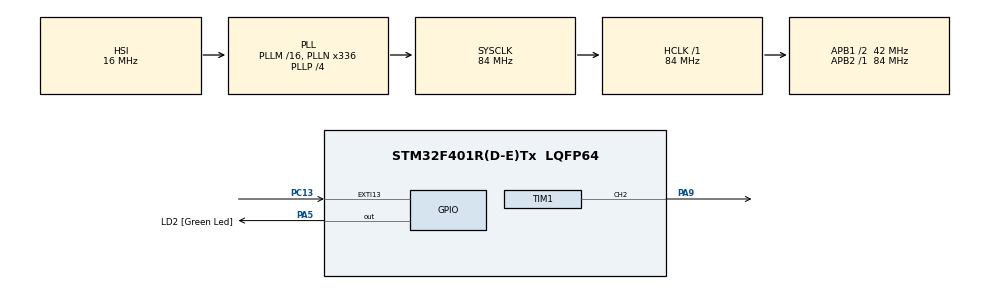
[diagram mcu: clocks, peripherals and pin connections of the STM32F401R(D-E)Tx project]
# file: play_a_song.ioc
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Mcu.Family=STM32F4
Mcu.Name=STM32F401R(D-E)Tx
Mcu.Package=LQFP64
NVIC.EXTI15_10_IRQn=true\:5\:0\:true\:false\:true\:true\:true
NVIC.PriorityGroup=NVIC_PRIORITYGROUP_4
NVIC.TIM1_BRK_TIM9_IRQn=true\:0\:0\:false\:false\:true\:true\:true
NVIC.TIM1_CC_IRQn=true\:0\:0\:false\:false\:true\:true\:true
NVIC.TIM1_TRG_COM_TIM11_IRQn=true\:0\:0\:false\:false\:true\:true\:true
NVIC.TIM1_UP_TIM10_IRQn=true\:0\:0\:false\:false\:true\:true\:true
NVIC.TIM2_IRQn=true\:0\:0\:false\:false\:true\:true\:true
PA13.GPIO_Label=TMS
PA13.Mode=Serial_Wire
PA13.Signal=SYS_JTMS-SWDIO
PA14.GPIO_Label=TCK
PA14.Mode=Serial_Wire
PA14.Signal=SYS_JTCK-SWCLK
PA5.GPIO_Label=LD2 [Green Led]
PA5.GPIO_Mode=GPIO_MODE_OUTPUT_PP
PA5.GPIO_PuPd=GPIO_NOPULL
PA5.GPIO_Speed=GPIO_SPEED_FREQ_LOW
PA5.Signal=GPIO_Output
PA9.Signal=S_TIM1_CH2
PB3.GPIO_Label=SWO
PB3.Signal=SYS_JTDO-SWO
PC13-ANTI_TAMP.Signal=GPXTI13
ProjectManager.HeapSize=0x200
ProjectManager.StackSize=0x400
ProjectManager.TargetToolchain=MDK-ARM V5
RCC.48MHZClocksFreq_Value=48000000
RCC.AHBFreq_Value=84000000
RCC.APB1CLKDivider=RCC_HCLK_DIV2
RCC.APB1Freq_Value=42000000
RCC.APB1TimFreq_Value=84000000
RCC.APB2Freq_Value=84000000
RCC.APB2TimFreq_Value=84000000
RCC.CortexFreq_Value=84000000
RCC.HCLKFreq_Value=84000000
RCC.HSE_VALUE=8000000
RCC.HSI_VALUE=16000000
RCC.LSE_VALUE=32768
RCC.PLLN=336
RCC.PLLP=RCC_PLLP_DIV4
RCC.PLLQ=7
RCC.SYSCLKFreq_VALUE=84000000
RCC.SYSCLKSource=RCC_SYSCLKSOURCE_PLLCLK
RCC.VCOOutputFreq_Value=336000000
SH.S_TIM1_CH2.0=TIM1_CH2,PWM Generation2 CH2
TIM1.Channel-PWM\ Generation2\ CH2=TIM_CHANNEL_2
TIM1.OCFastMode_PWM-PWM\ Generation2\ CH2=TIM_OCFAST_DISABLE
TIM1.Period=480-1
TIM1.Prescaler=84-1
TIM1.Pulse-PWM\ Generation2\ CH2=240-1
TIM2.Period=42-1
TIM2.Prescaler=2000-1
TIM2.TIM_MasterOutputTrigger=TIM_TRGO_OC1REF
TIM2.TIM_MasterSlaveMode=TIM_MASTERSLAVEMODE_DISABLE
VP_TIM1_VS_ClockSourceINT.Mode=Internal
VP_TIM2_VS_ClockSourceINT.Mode=Internal
board=NUCLEO-F401RE

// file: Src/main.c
/* USER CODE BEGIN Header */
/**
  ******************************************************************************
  * @file           : main.c
  * @brief          : Main program body
  ******************************************************************************
  * @attention
  *
  * <h2><center>&copy; Copyright (c) 2019 STMicroelectronics.
  * All rights reserved.</center></h2>
  *
  * This software component is licensed by ST under BSD 3-Clause license,
  * the "License"; You may not use this file except in compliance with the
  * License. You may obtain a copy of the License at:
  *                        opensource.org/licenses/BSD-3-Clause
  *
  ******************************************************************************
  */
/* USER CODE END Header */

#include "main.h"

/* USER CODE BEGIN PD */
#define MIN 60		// how many seconds in a minute
#define MS 1000		// milliseconds
#define BPM 35		// beats-per-minute

// Period of each note in ms
#define NOTE_B0    32396
#define NOTE_C1    30578
#define NOTE_CS1   28862
#define NOTE_D1    27242
#define NOTE_DS1   25713
#define NOTE_E1    24270
#define NOTE_F1    22908
#define NOTE_FS1   21622
#define NOTE_G1    20408
#define NOTE_GS1   19263
#define NOTE_A1    18182
#define NOTE_AS1   17161
#define NOTE_B1    16198
#define NOTE_C2    15289
#define NOTE_CS2   14431
#define NOTE_D2    13621
#define NOTE_DS2   12856
#define NOTE_E2    12135
#define NOTE_F2    11454
#define NOTE_FS2   10811
#define NOTE_G2    10204
#define NOTE_GS2    9631
#define NOTE_A2     9091
#define NOTE_AS2    8581
#define NOTE_B2     8099
#define NOTE_C3     7645
#define NOTE_CS3    7215
#define NOTE_D3     6810
#define NOTE_DS3    6428
#define NOTE_E3     6067
#define NOTE_F3     5727
#define NOTE_FS3    5405
#define NOTE_G3     5102
#define NOTE_GS3    4816
#define NOTE_A3     4545
#define NOTE_AS3    4290
#define NOTE_B3     4050
#define NOTE_C4     3822
#define NOTE_CS4    3608
#define NOTE_D4     3405
#define NOTE_DS4    3214
#define NOTE_E4     3034
#define NOTE_F4     2863
#define NOTE_FS4    2703
#define NOTE_G4     2551
#define NOTE_GS4    2408
#define NOTE_A4     2273
#define NOTE_AS4    2145
#define NOTE_B4     2025
#define NOTE_C5     1911
#define NOTE_CS5    1804
#define NOTE_D5     1703
#define NOTE_DS5    1607
#define NOTE_E5     1517
#define NOTE_F5     1432
#define NOTE_FS5    1351
#define NOTE_G5     1276
#define NOTE_GS5    1204
#define NOTE_A5     1136
#define NOTE_AS5    1073
#define NOTE_B5     1012
#define NOTE_C6      956
#define NOTE_CS6     902
#define NOTE_D6      851
#define NOTE_DS6     804
#define NOTE_E6      758
#define NOTE_F6      716
#define NOTE_FS6     676
#define NOTE_G6      638
#define NOTE_GS6     602
#define NOTE_A6      568
#define NOTE_AS6     536
#define NOTE_B6      506
#define NOTE_C7      478
#define NOTE_CS7     451
#define NOTE_D7      426
#define NOTE_DS7     402
#define NOTE_E7      379
#define NOTE_F7      358
#define NOTE_FS7     338
#define NOTE_G7      319
#define NOTE_GS7     301
#define NOTE_A7      284
#define NOTE_AS7     268
#define NOTE_B7      253
#define NOTE_C8      239
/* USER CODE END PD */

TIM_HandleTypeDef htim1;
TIM_HandleTypeDef htim2;

/* USER CODE BEGIN PV */
int notes[] = {
	NOTE_E7, NOTE_E7, 0, NOTE_E7,
  0, NOTE_C7, NOTE_E7, 0,
  NOTE_G7, 0, 0,  0,
  NOTE_G6, 0, 0, 0,

	NOTE_C7, 0, 0, NOTE_G6,
  0, 0, NOTE_E6, 0,
  0, NOTE_A6, 0, NOTE_B6,
  0, NOTE_AS6, NOTE_A6, 0,

  NOTE_G6, NOTE_E7, NOTE_G7,
  NOTE_A7, 0, NOTE_F7, NOTE_G7,
  0, NOTE_E7, 0, NOTE_C7,
  NOTE_D7, NOTE_B6, 0, 0,

  NOTE_C7, 0, 0, NOTE_G6,
  0, 0, NOTE_E6, 0,
  0, NOTE_A6, 0, NOTE_B6,
  0, NOTE_AS6, NOTE_A6, 0,

  NOTE_G6, NOTE_E7, NOTE_G7,
  NOTE_A7, 0, NOTE_F7, NOTE_G7,
  0, NOTE_E7, 0, NOTE_C7,
  NOTE_D7, NOTE_B6, 0, 0

};
int duration[] = {
	12, 12, 12, 12,
  12, 12, 12, 12,
  12, 12, 12, 12,
  12, 12, 12, 12,

	12, 12, 12, 12,
  12, 12, 12, 12,
  12, 12, 12, 12,
  12, 12, 12, 12,

  9, 9, 9,
  12, 12, 12, 12,
  12, 12, 12, 12,
  12, 12, 12, 12,

  12, 12, 12, 12,
  12, 12, 12, 12,
  12, 12, 12, 12,
  12, 12, 12, 12,

  9, 9, 9,
  12, 12, 12, 12,
  12, 12, 12, 12,
  12, 12, 12, 12

};	// beat
unsigned int counter = 0;
unsigned int i;
unsigned int note_duration, beat;
unsigned int flag = 0;
/* USER CODE END PV */

void SystemClock_Config(void);
static void MX_GPIO_Init(void);
static void MX_TIM1_Init(void);
static void MX_TIM2_Init(void);
/* USER CODE BEGIN PFP */
void play_song(void);
/* USER CODE END PFP */

int main(void)
{

  /* MCU Configuration--------------------------------------------------------*/

  /* Reset of all peripherals, Initializes the Flash interface and the Systick. */
  HAL_Init();

  /* Configure the system clock */
  SystemClock_Config();

  /* Initialize all configured peripherals */
  MX_GPIO_Init();
  MX_TIM1_Init();
  MX_TIM2_Init();
  /* USER CODE BEGIN 2 */
	beat = MIN*MS/BPM;
  /* USER CODE END 2 */

  /* Infinite loop */
  while (1)
  {

  }
}

void SystemClock_Config(void)
{
  RCC_OscInitTypeDef RCC_OscInitStruct = {0};
  RCC_ClkInitTypeDef RCC_ClkInitStruct = {0};

  /** Configure the main internal regulator output voltage
  */
  __HAL_RCC_PWR_CLK_ENABLE();
  __HAL_PWR_VOLTAGESCALING_CONFIG(PWR_REGULATOR_VOLTAGE_SCALE2);
  /** Initializes the CPU, AHB and APB busses clocks
  */
  RCC_OscInitStruct.OscillatorType = RCC_OSCILLATORTYPE_HSI;
  RCC_OscInitStruct.HSIState = RCC_HSI_ON;
  RCC_OscInitStruct.HSICalibrationValue = RCC_HSICALIBRATION_DEFAULT;
  RCC_OscInitStruct.PLL.PLLState = RCC_PLL_ON;
  RCC_OscInitStruct.PLL.PLLSource = RCC_PLLSOURCE_HSI;
  RCC_OscInitStruct.PLL.PLLM = 16;
  RCC_OscInitStruct.PLL.PLLN = 336;
  RCC_OscInitStruct.PLL.PLLP = RCC_PLLP_DIV4;
  RCC_OscInitStruct.PLL.PLLQ = 7;
  if (HAL_RCC_OscConfig(&RCC_OscInitStruct) != HAL_OK)
  {
    Error_Handler();
  }
  /** Initializes the CPU, AHB and APB busses clocks
  */
  RCC_ClkInitStruct.ClockType = RCC_CLOCKTYPE_HCLK|RCC_CLOCKTYPE_SYSCLK
                              |RCC_CLOCKTYPE_PCLK1|RCC_CLOCKTYPE_PCLK2;
  RCC_ClkInitStruct.SYSCLKSource = RCC_SYSCLKSOURCE_PLLCLK;
  RCC_ClkInitStruct.AHBCLKDivider = RCC_SYSCLK_DIV1;
  RCC_ClkInitStruct.APB1CLKDivider = RCC_HCLK_DIV2;
  RCC_ClkInitStruct.APB2CLKDivider = RCC_HCLK_DIV1;

  if (HAL_RCC_ClockConfig(&RCC_ClkInitStruct, FLASH_LATENCY_2) != HAL_OK)
  {
    Error_Handler();
  }
}

static void MX_TIM1_Init(void)
{

  TIM_ClockConfigTypeDef sClockSourceConfig = {0};
  TIM_MasterConfigTypeDef sMasterConfig = {0};
  TIM_OC_InitTypeDef sConfigOC = {0};
  TIM_BreakDeadTimeConfigTypeDef sBreakDeadTimeConfig = {0};

  htim1.Instance = TIM1;
  htim1.Init.Prescaler = 84-1;
  htim1.Init.CounterMode = TIM_COUNTERMODE_UP;
  htim1.Init.Period = 480-1;
  htim1.Init.ClockDivision = TIM_CLOCKDIVISION_DIV1;
  htim1.Init.RepetitionCounter = 0;
  htim1.Init.AutoReloadPreload = TIM_AUTORELOAD_PRELOAD_DISABLE;
  if (HAL_TIM_Base_Init(&htim1) != HAL_OK)
  {
    Error_Handler();
  }
  sClockSourceConfig.ClockSource = TIM_CLOCKSOURCE_INTERNAL;
  if (HAL_TIM_ConfigClockSource(&htim1, &sClockSourceConfig) != HAL_OK)
  {
    Error_Handler();
  }
  if (HAL_TIM_PWM_Init(&htim1) != HAL_OK)
  {
    Error_Handler();
  }
  sMasterConfig.MasterOutputTrigger = TIM_TRGO_RESET;
  sMasterConfig.MasterSlaveMode = TIM_MASTERSLAVEMODE_DISABLE;
  if (HAL_TIMEx_MasterConfigSynchronization(&htim1, &sMasterConfig) != HAL_OK)
  {
    Error_Handler();
  }
  sConfigOC.OCMode = TIM_OCMODE_PWM1;
  sConfigOC.Pulse = 240-1;
  sConfigOC.OCPolarity = TIM_OCPOLARITY_HIGH;
  sConfigOC.OCNPolarity = TIM_OCNPOLARITY_HIGH;
  sConfigOC.OCFastMode = TIM_OCFAST_DISABLE;
  sConfigOC.OCIdleState = TIM_OCIDLESTATE_RESET;
  sConfigOC.OCNIdleState = TIM_OCNIDLESTATE_RESET;
  if (HAL_TIM_PWM_ConfigChannel(&htim1, &sConfigOC, TIM_CHANNEL_2) != HAL_OK)
  {
    Error_Handler();
  }
  sBreakDeadTimeConfig.OffStateRunMode = TIM_OSSR_DISABLE;
  sBreakDeadTimeConfig.OffStateIDLEMode = TIM_OSSI_DISABLE;
  sBreakDeadTimeConfig.LockLevel = TIM_LOCKLEVEL_OFF;
  sBreakDeadTimeConfig.DeadTime = 0;
  sBreakDeadTimeConfig.BreakState = TIM_BREAK_DISABLE;
  sBreakDeadTimeConfig.BreakPolarity = TIM_BREAKPOLARITY_HIGH;
  sBreakDeadTimeConfig.AutomaticOutput = TIM_AUTOMATICOUTPUT_DISABLE;
  if (HAL_TIMEx_ConfigBreakDeadTime(&htim1, &sBreakDeadTimeConfig) != HAL_OK)
  {
    Error_Handler();
  }
  HAL_TIM_MspPostInit(&htim1);

}

static void MX_TIM2_Init(void)
{

  TIM_ClockConfigTypeDef sClockSourceConfig = {0};
  TIM_MasterConfigTypeDef sMasterConfig = {0};

  htim2.Instance = TIM2;
  htim2.Init.Prescaler = 2000-1;
  htim2.Init.CounterMode = TIM_COUNTERMODE_UP;
  htim2.Init.Period = 42-1;
  htim2.Init.ClockDivision = TIM_CLOCKDIVISION_DIV1;
  htim2.Init.AutoReloadPreload = TIM_AUTORELOAD_PRELOAD_DISABLE;
  if (HAL_TIM_Base_Init(&htim2) != HAL_OK)
  {
    Error_Handler();
  }
  sClockSourceConfig.ClockSource = TIM_CLOCKSOURCE_INTERNAL;
  if (HAL_TIM_ConfigClockSource(&htim2, &sClockSourceConfig) != HAL_OK)
  {
    Error_Handler();
  }
  sMasterConfig.MasterOutputTrigger = TIM_TRGO_OC1REF;
  sMasterConfig.MasterSlaveMode = TIM_MASTERSLAVEMODE_DISABLE;
  if (HAL_TIMEx_MasterConfigSynchronization(&htim2, &sMasterConfig) != HAL_OK)
  {
    Error_Handler();
  }

}

static void MX_GPIO_Init(void)
{
  GPIO_InitTypeDef GPIO_InitStruct = {0};

  /* GPIO Ports Clock Enable */
  __HAL_RCC_GPIOC_CLK_ENABLE();
  __HAL_RCC_GPIOA_CLK_ENABLE();
  __HAL_RCC_GPIOB_CLK_ENABLE();

  /*Configure GPIO pin Output Level */
  HAL_GPIO_WritePin(LD2_GPIO_Port, LD2_Pin, GPIO_PIN_RESET);

  /*Configure GPIO pin : PC13 */
  GPIO_InitStruct.Pin = GPIO_PIN_13;
  GPIO_InitStruct.Mode = GPIO_MODE_IT_RISING;
  GPIO_InitStruct.Pull = GPIO_NOPULL;
  HAL_GPIO_Init(GPIOC, &GPIO_InitStruct);

  /*Configure GPIO pin : LD2_Pin */
  GPIO_InitStruct.Pin = LD2_Pin;
  GPIO_InitStruct.Mode = GPIO_MODE_OUTPUT_PP;
  GPIO_InitStruct.Pull = GPIO_NOPULL;
  GPIO_InitStruct.Speed = GPIO_SPEED_FREQ_LOW;
  HAL_GPIO_Init(LD2_GPIO_Port, &GPIO_InitStruct);

  /* EXTI interrupt init*/
  HAL_NVIC_SetPriority(EXTI15_10_IRQn, 5, 0);
  HAL_NVIC_EnableIRQ(EXTI15_10_IRQn);

}

/* USER CODE BEGIN 4 */
void HAL_GPIO_EXTI_Callback(uint16_t GPIO_Pin)
{
	switch(GPIO_Pin)
	{
		case GPIO_PIN_13:
			flag = 1;
			i = 0;
			HAL_TIM_Base_Start_IT(&htim1); // prepare timer 1 to gen PWM
			__HAL_GPIO_EXTI_CLEAR_FLAG(GPIO_Pin);	// clear blue button interrupt flag
			HAL_Delay(200);
			play_song();
			break;
	}
}

void play_song(){
	do{
		if (flag == 1){
			// (flag == 1) --> note played
			// (flag == 0) --> note playing
			flag = 0;

			// get TIM1 ready to play the right note
			TIM1->ARR = notes[i]-1;																	// Auto Reload Resgister [ms]
			TIM1->CCR2 = (notes[i]-1)/2;														// Pulse [ms]

			// get TIM2 ready to keep track of note duration
			note_duration = beat/duration[i];
			counter = 0;

			// 'start' both timers
			HAL_TIM_PWM_Start(&htim1, TIM_CHANNEL_2);								// start tone
			HAL_TIM_Base_Start_IT(&htim2);													// start counting for note duration

			// prepare to play next note (if it exists)
			i++;

			// check if button is pressed again
			if(EXTI->PR == GPIO_PIN_13)
			{
				__HAL_GPIO_EXTI_CLEAR_FLAG(GPIO_PIN_13);
				//i = sizeof(notes)/4;
				//counter = beat/duration[i];
				counter = 0;
				flag = 0;
				i=0;
				HAL_TIM_PWM_Stop(&htim1, TIM_CHANNEL_2);								// stop tone (PWM gen by TIM1 on CH2)
				HAL_TIM_Base_Stop_IT(&htim2);
				break;
			}
		}
	}while(i<sizeof(notes)/4);
	// STOP SONG (RESET CONDITIONS)
	counter = 0;
	flag = 0;
	i=0;
	HAL_TIM_PWM_Stop(&htim1, TIM_CHANNEL_2);								// stop tone (PWM gen by TIM1 on CH2)
	HAL_TIM_Base_Stop_IT(&htim2);
}

void HAL_TIM_PeriodElapsedCallback(TIM_HandleTypeDef *htim)		// 1 cycle elapsed
{
	if(htim->Instance == TIM1) 																	// check that it was called by Timer 1
	{
		// timer 1 instructions
	}
	if(htim->Instance == TIM2) 																	// check that it was called by Timer 2
	{
		counter ++;																								// increase counter to keep track of the # of ms elapsed
		if (counter > note_duration){															// counter exceeds note duration
			HAL_TIM_PWM_Stop(&htim1, TIM_CHANNEL_2);								// stop tone (PWM gen by TIM1 on CH2)
			HAL_TIM_Base_Stop_IT(&htim2);
			flag = 1;																								// go to next note
		}
	}
}
/* USER CODE END 4 */

void Error_Handler(void)
{
}

/************************ (C) COPYRIGHT STMicroelectronics *****END OF FILE****/
